AUTOSAR XML (schema 4-0-3)
standard types defined: UInt8
package /AUTOSAR_Platform/DataConstrs
  range DC_UInt8: raw 0..255
package /PATAC/MSM/ComponentTypes
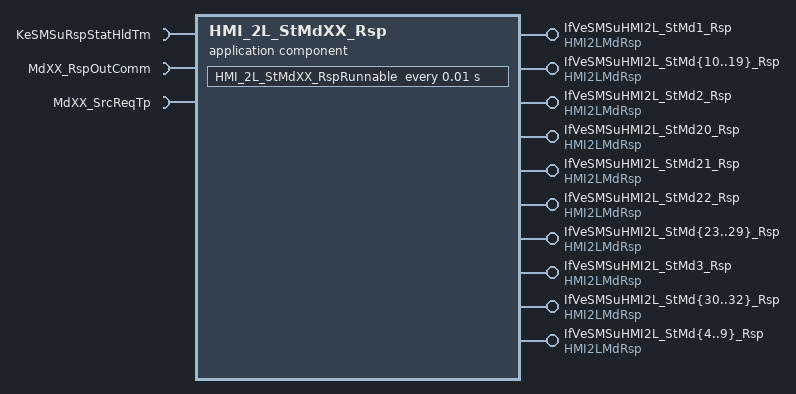
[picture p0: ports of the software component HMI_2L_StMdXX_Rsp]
  application sw component type HMI_2L_StMdXX_Rsp
    32 x provide port, all with provided-interface=HMI2LMdRsp:
      IfVeSMSuHMI2L_StMd1_Rsp: nonqueued-sender-com-spec=data-element=Val
      IfVeSMSuHMI2L_StMd{10..19}_Rsp: nonqueued-sender-com-spec=data-element=Val
      IfVeSMSuHMI2L_StMd2_Rsp: nonqueued-sender-com-spec=data-element=Val
      IfVeSMSuHMI2L_StMd20_Rsp: nonqueued-sender-com-spec=data-element=Val
      IfVeSMSuHMI2L_StMd21_Rsp: nonqueued-sender-com-spec=data-element=Val
      IfVeSMSuHMI2L_StMd22_Rsp: nonqueued-sender-com-spec{data-element=Val, init-value=0}
      IfVeSMSuHMI2L_StMd{23..29}_Rsp: nonqueued-sender-com-spec=data-element=Val
      IfVeSMSuHMI2L_StMd3_Rsp: nonqueued-sender-com-spec=data-element=Val
      IfVeSMSuHMI2L_StMd{30..32}_Rsp: nonqueued-sender-com-spec=data-element=Val
      IfVeSMSuHMI2L_StMd{4..9}_Rsp: nonqueued-sender-com-spec=data-element=Val
    require port KeSMSuRspStatHldTm: parameter-require-com-spec{init-value=100, parameter=Val}, required-interface=KeSMSuRspStatHldTm
    require port MdXX_RspOutComm: required-interface=MdXX_RspOutComm
      required-com-specs:
        data-element=Md1_RspOutComm, filter=data-filter-type=ALWAYS, init-value=0
        data-element=Md{10..19}_RspOutComm, filter=data-filter-type=ALWAYS, init-value=0
        data-element=Md2_RspOutComm, filter=data-filter-type=ALWAYS, init-value=0
        data-element=Md{20..29}_RspOutComm, filter=data-filter-type=ALWAYS, init-value=0
        data-element=Md3_RspOutComm, filter=data-filter-type=ALWAYS, init-value=0
        data-element=Md{30..32}_RspOutComm, filter=data-filter-type=ALWAYS, init-value=0
        data-element=Md{4..9}_RspOutComm, filter=data-filter-type=ALWAYS, init-value=0
    require port MdXX_SrcReqTp: required-interface=MdXX_SrcReqTp
      required-com-specs:
        data-element=Md1_SrcTp, filter=data-filter-type=ALWAYS, init-value=0
        data-element=Md{10..19}_SrcTp, filter=data-filter-type=ALWAYS, init-value=0
        data-element=Md2_SrcTp, filter=data-filter-type=ALWAYS, init-value=0
        data-element=Md{20..29}_SrcTp, filter=data-filter-type=ALWAYS, init-value=0
        data-element=Md3_SrcTp, filter=data-filter-type=ALWAYS, init-value=0
        data-element=Md{30..32}_SrcTp, filter=data-filter-type=ALWAYS, init-value=0
        data-element=Md{4..9}_SrcTp, filter=data-filter-type=ALWAYS, init-value=0
    behavior HMI_2L_StMdXX_Rsp_InternalBehavior
      timing event TMT_HMI_2L_StMdXX_RspRunnable: start-on-event=HMI_2L_StMdXX_RspRunnable, period=0.01
      runnable HMI_2L_StMdXX_RspRunnable
        data-receive-point-by-arguments:
          64 x access:
            REC_MdXX_RspOutComm_Md1_RspOutComm: accessed-variable=MdXX_RspOutComm.Md1_RspOutComm
            REC_MdXX_RspOutComm_Md{10..19}_RspOutComm: accessed-variable=MdXX_RspOutComm.Md{10..19}_RspOutComm
            REC_MdXX_RspOutComm_Md2_RspOutComm: accessed-variable=MdXX_RspOutComm.Md2_RspOutComm
            REC_MdXX_RspOutComm_Md{20..29}_RspOutComm: accessed-variable=MdXX_RspOutComm.Md{20..29}_RspOutComm
            REC_MdXX_RspOutComm_Md3_RspOutComm: accessed-variable=MdXX_RspOutComm.Md3_RspOutComm
            REC_MdXX_RspOutComm_Md{30..32}_RspOutComm: accessed-variable=MdXX_RspOutComm.Md{30..32}_RspOutComm
            REC_MdXX_RspOutComm_Md{4..9}_RspOutComm: accessed-variable=MdXX_RspOutComm.Md{4..9}_RspOutComm
            REC_MdXX_SrcReqTp_Md1_SrcTp: accessed-variable=MdXX_SrcReqTp.Md1_SrcTp
            REC_MdXX_SrcReqTp_Md{10..19}_SrcTp: accessed-variable=MdXX_SrcReqTp.Md{10..19}_SrcTp
            REC_MdXX_SrcReqTp_Md2_SrcTp: accessed-variable=MdXX_SrcReqTp.Md2_SrcTp
            REC_MdXX_SrcReqTp_Md{20..29}_SrcTp: accessed-variable=MdXX_SrcReqTp.Md{20..29}_SrcTp
            REC_MdXX_SrcReqTp_Md3_SrcTp: accessed-variable=MdXX_SrcReqTp.Md3_SrcTp
            REC_MdXX_SrcReqTp_Md{30..32}_SrcTp: accessed-variable=MdXX_SrcReqTp.Md{30..32}_SrcTp
            REC_MdXX_SrcReqTp_Md{4..9}_SrcTp: accessed-variable=MdXX_SrcReqTp.Md{4..9}_SrcTp
        data-send-points:
          32 x access:
            SEND_IfVeSMSuHMI2L_StMd1_Rsp_Val: accessed-variable=IfVeSMSuHMI2L_StMd1_Rsp.Val
            SEND_IfVeSMSuHMI2L_StMd{10..19}_Rsp_Val: accessed-variable=IfVeSMSuHMI2L_StMd{10..19}_Rsp.Val
            SEND_IfVeSMSuHMI2L_StMd2_Rsp_Val: accessed-variable=IfVeSMSuHMI2L_StMd2_Rsp.Val
            SEND_IfVeSMSuHMI2L_StMd{20..29}_Rsp_Val: accessed-variable=IfVeSMSuHMI2L_StMd{20..29}_Rsp.Val
            SEND_IfVeSMSuHMI2L_StMd3_Rsp_Val: accessed-variable=IfVeSMSuHMI2L_StMd3_Rsp.Val
            SEND_IfVeSMSuHMI2L_StMd{30..32}_Rsp_Val: accessed-variable=IfVeSMSuHMI2L_StMd{30..32}_Rsp.Val
            SEND_IfVeSMSuHMI2L_StMd{4..9}_Rsp_Val: accessed-variable=IfVeSMSuHMI2L_StMd{4..9}_Rsp.Val
        parameter access PA_KeSMSuRspStatHldTm_Val: accessed-parameter=KeSMSuRspStatHldTm.Val
  swc implementation HMI_2L_StMdXX_Rsp_Implementation: behavior=HMI_2L_StMdXX_Rsp_InternalBehavior
    code-descriptors:
      code Default: artifact-descriptors=autosar-engineering-object={short-label=Default, category=SWSRC}
package /PATAC/MSM/ModeAdjust/CalPortInterface
  parameter interface KeSMSuRspStatHldTm
    parameter data prototype Val: sw-calibration-access=READ-WRITE, type=UInt8
package /PATAC/MSM/ModeAdjust/DataType
  impl type SrcReqTp1: category=VALUE, base-type=UInt8, sw-calibration-access=READ-ONLY, compu {0=SrcReqTp_None, 1=SrcReqTp_Local, 2=SrcReqTp_HMI2L, 3=SrcReqTp_HMI2R, 4=SrcReqTp_HMI, 5=SrcReqTp_Remote, 6=SrcReqTp_SRS}, type-emitter=RTE
package /PATAC/MSM/ModeAdjust/PortInterface
  sender receiver interface HMI2LMdRsp: invalidation-policy{data-element=Val, handle-invalid=DONT-INVALIDATE}
    data Val: type=UInt8
  sender receiver interface MdXX_RspOutComm
    32 x data, all with type=UInt8:
      Md1_RspOutComm
      Md{10..19}_RspOutComm
      Md2_RspOutComm
      Md{20..29}_RspOutComm
      Md3_RspOutComm
      Md{30..32}_RspOutComm
      Md{4..9}_RspOutComm
    invalidation-policys:
      data-element=Md1_RspOutComm, handle-invalid=DONT-INVALIDATE
      data-element=Md11_RspOutComm, handle-invalid=DONT-INVALIDATE
      data-element=Md12_RspOutComm, handle-invalid=DONT-INVALIDATE
      data-element=Md14_RspOutComm, handle-invalid=DONT-INVALIDATE
      data-element=Md13_RspOutComm, handle-invalid=DONT-INVALIDATE
      data-element=Md19_RspOutComm, handle-invalid=DONT-INVALIDATE
      data-element=Md15_RspOutComm, handle-invalid=DONT-INVALIDATE
      data-element=Md18_RspOutComm, handle-invalid=DONT-INVALIDATE
      data-element=Md16_RspOutComm, handle-invalid=DONT-INVALIDATE
      data-element=Md17_RspOutComm, handle-invalid=DONT-INVALIDATE
      data-element=Md2_RspOutComm, handle-invalid=DONT-INVALIDATE
      data-element=Md21_RspOutComm, handle-invalid=DONT-INVALIDATE
      data-element=Md22_RspOutComm, handle-invalid=DONT-INVALIDATE
      data-element=Md24_RspOutComm, handle-invalid=DONT-INVALIDATE
      data-element=Md23_RspOutComm, handle-invalid=DONT-INVALIDATE
      data-element=Md{25..27}_RspOutComm, handle-invalid=DONT-INVALIDATE
      data-element=Md29_RspOutComm, handle-invalid=DONT-INVALIDATE
      data-element=Md28_RspOutComm, handle-invalid=DONT-INVALIDATE
      data-element=Md3_RspOutComm, handle-invalid=DONT-INVALIDATE
      data-element=Md31_RspOutComm, handle-invalid=DONT-INVALIDATE
      data-element=Md32_RspOutComm, handle-invalid=DONT-INVALIDATE
      data-element=Md{4..6}_RspOutComm, handle-invalid=DONT-INVALIDATE
      data-element=Md9_RspOutComm, handle-invalid=DONT-INVALIDATE
      data-element=Md7_RspOutComm, handle-invalid=DONT-INVALIDATE
      data-element=Md8_RspOutComm, handle-invalid=DONT-INVALIDATE
      data-element=Md10_RspOutComm, handle-invalid=DONT-INVALIDATE
      data-element=Md20_RspOutComm, handle-invalid=DONT-INVALIDATE
      data-element=Md30_RspOutComm, handle-invalid=DONT-INVALIDATE
  sender receiver interface MdXX_SrcReqTp
    32 x data, all with type=SrcReqTp1:
      Md1_SrcTp
      Md{10..19}_SrcTp
      Md2_SrcTp
      Md{20..29}_SrcTp
      Md3_SrcTp
      Md{30..32}_SrcTp
      Md{4..9}_SrcTp
    invalidation-policys:
      data-element=Md1_SrcTp, handle-invalid=DONT-INVALIDATE
      data-element=Md2_SrcTp, handle-invalid=DONT-INVALIDATE
      data-element=Md4_SrcTp, handle-invalid=DONT-INVALIDATE
      data-element=Md3_SrcTp, handle-invalid=DONT-INVALIDATE
      data-element=Md6_SrcTp, handle-invalid=DONT-INVALIDATE
      data-element=Md5_SrcTp, handle-invalid=DONT-INVALIDATE
      data-element=Md10_SrcTp, handle-invalid=DONT-INVALIDATE
      data-element=Md7_SrcTp, handle-invalid=DONT-INVALIDATE
      data-element=Md12_SrcTp, handle-invalid=DONT-INVALIDATE
      data-element=Md8_SrcTp, handle-invalid=DONT-INVALIDATE
      data-element=Md11_SrcTp, handle-invalid=DONT-INVALIDATE
      data-element=Md9_SrcTp, handle-invalid=DONT-INVALIDATE
      data-element=Md14_SrcTp, handle-invalid=DONT-INVALIDATE
      data-element=Md13_SrcTp, handle-invalid=DONT-INVALIDATE
      data-element=Md17_SrcTp, handle-invalid=DONT-INVALIDATE
      data-element=Md16_SrcTp, handle-invalid=DONT-INVALIDATE
      data-element=Md15_SrcTp, handle-invalid=DONT-INVALIDATE
      data-element=Md19_SrcTp, handle-invalid=DONT-INVALIDATE
      data-element=Md18_SrcTp, handle-invalid=DONT-INVALIDATE
      data-element=Md{20..22}_SrcTp, handle-invalid=DONT-INVALIDATE
      data-element=Md24_SrcTp, handle-invalid=DONT-INVALIDATE
      data-element=Md23_SrcTp, handle-invalid=DONT-INVALIDATE
      data-element=Md26_SrcTp, handle-invalid=DONT-INVALIDATE
      data-element=Md25_SrcTp, handle-invalid=DONT-INVALIDATE
      data-element=Md28_SrcTp, handle-invalid=DONT-INVALIDATE
      data-element=Md27_SrcTp, handle-invalid=DONT-INVALIDATE
      data-element=Md30_SrcTp, handle-invalid=DONT-INVALIDATE
      data-element=Md29_SrcTp, handle-invalid=DONT-INVALIDATE
      data-element=Md32_SrcTp, handle-invalid=DONT-INVALIDATE
      data-element=Md31_SrcTp, handle-invalid=DONT-INVALIDATE
